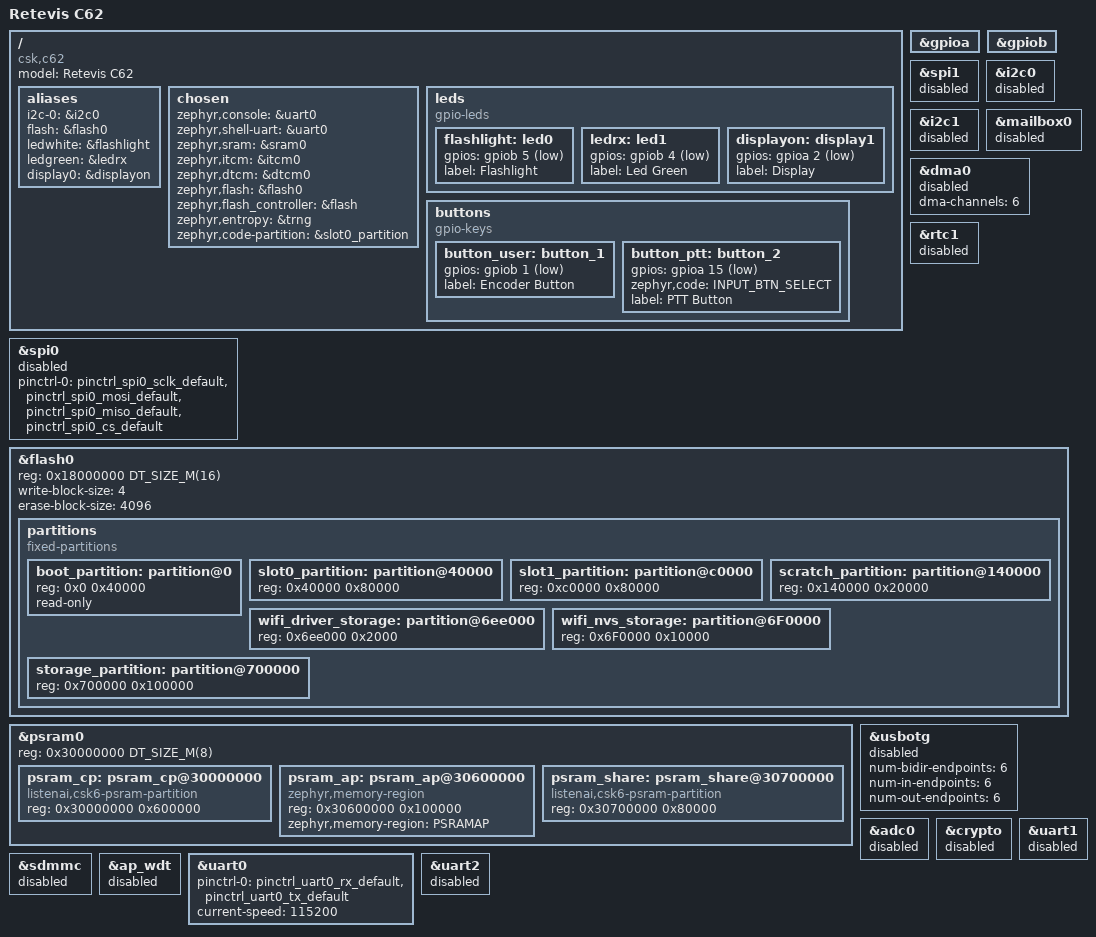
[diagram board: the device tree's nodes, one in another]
/* SPDX-License-Identifier: Apache-2.0 */

/dts-v1/;
#include <csk/csk6011b.dtsi>
#include <zephyr/dt-bindings/pwm/pwm.h>
#include <zephyr/dt-bindings/gpio/gpio.h>
#include <zephyr/dt-bindings/input/input-event-codes.h>
#include "c62_pinctrl.dtsi"

/ {
        model = "Retevis C62";
        compatible = "csk,c62";
        aliases {
                i2c-0 = &i2c0;
                flash = &flash0;

                ledwhite = &flashlight;
                ledgreen = &ledrx;


                display0 = &displayon;
        };

        chosen {
                zephyr,console = &uart0;
                zephyr,shell-uart = &uart0;
                zephyr,sram = &sram0;
                zephyr,itcm = &itcm0;
                zephyr,dtcm = &dtcm0;
                zephyr,flash = &flash0;
                zephyr,flash_controller = &flash;
                zephyr,entropy = &trng;
                zephyr,code-partition = &slot0_partition;
                /* other chosen settings  for your hardware */
        };

        leds {
                compatible = "gpio-leds";
                flashlight: led0 {
                        gpios = <&gpiob 5 GPIO_ACTIVE_LOW>;
                        label = "Flashlight";
                };
                ledrx: led1 {
                        gpios = <&gpiob 4 GPIO_ACTIVE_LOW>;
                        label = "Led Green";
                };
                displayon: display1 {
                        gpios = <&gpioa 2 GPIO_ACTIVE_LOW>;
                        label = "Display";
                };
        };

        buttons: buttons  {
                compatible = "gpio-keys";
                
                button_user: button_1 {
                        gpios = <&gpiob 1 (GPIO_PULL_UP | GPIO_ACTIVE_LOW)>;
                        label = "Encoder Button";
                };
                
                button_ptt: button_2 {
                        gpios = <&gpioa 15 (GPIO_PULL_UP | GPIO_ACTIVE_LOW)>;
                        zephyr,code = <INPUT_BTN_SELECT>;
                        label = "PTT Button";
                };
        };


        /*
         * Your board-specific hardware: buttons, LEDs, sensors, etc.
         */
};


&gpioa {
        status = "okay";
};

&gpiob {
        status = "okay";
};

&spi0 {
        pinctrl-0 = <&pinctrl_spi0_sclk_default &pinctrl_spi0_mosi_default &pinctrl_spi0_miso_default &pinctrl_spi0_cs_default>;
        pinctrl-names = "default";
        status = "disabled";
};

&spi1 {
        status = "disabled";
};

&i2c0 {
        status = "disabled";
};

&i2c1 {
        status = "disabled";
};

&mailbox0 {
        status = "disabled";
};

&dma0 {
        dma-channels = <6>;
        status = "disabled";
};

&rtc1 {
        status = "disabled";
};

&flash0 {
        /*
         * For more information, see:
         * http: //docs.zephyrproject.org/latest/guides/dts/index.html#flash-partitions
         */
        reg = <0x18000000 DT_SIZE_M(16)>;
        write-block-size = <4>;
        erase-block-size = <4096>;
        partitions {
                compatible = "fixed-partitions";
                #address-cells = <1>;
                #size-cells = <1>;

                /* 256KB for bootloader */
                boot_partition: partition@0 {
                        reg = <0x0 0x40000>;
                        read-only;
                };

                /* application image slot: 512KB */
                slot0_partition: partition@40000 {
                        reg = <0x40000 0x80000>;
                };

                /* backup slot: 512KB */
                slot1_partition: partition@c0000 {
                        reg = <0xc0000 0x80000>;
                };

                /* swap slot: 128KB */
                scratch_partition: partition@140000 {
                        reg = <0x140000 0x20000>;
                };

                /* wifi driver private storage: 8Kb */
                wifi_driver_storage: partition@6ee000 {
                        reg = <0x6ee000 0x2000>;
                };

                /* wifi_nvs_storage: 20Kb */
                wifi_nvs_storage: partition@6F0000 {
                        reg = <0x6F0000 0x10000>;
                };

                /* storage: 6.625MB for storage */
                storage_partition: partition@700000 {
                        reg = <0x700000 0x100000>;
                };


        };
};

&psram0 {
        reg = <0x30000000 DT_SIZE_M(8)>;
        #address-cells = <1>;
        #size-cells = <1>;

        /*psram for cp core slot: 6MB */
        psram_cp: psram_cp@30000000 {
                compatible = "listenai,csk6-psram-partition";
                reg = <0x30000000 0x600000>;
                status = "okay";
        };

        /*psram for ap core slot: 1MB */
        psram_ap: psram_ap@30600000 {
                compatible = "zephyr,memory-region",
                             "listenai,csk6-psram-partition";
                reg = <0x30600000 0x100000>;
                status = "okay";
                zephyr,memory-region = "PSRAMAP";
        };

        /*psram for ap share with cp slot: 512KB */
        psram_share: psram_share@30700000 {
                compatible = "listenai,csk6-psram-partition";
                reg = <0x30700000 0x80000>;
                status = "okay";
        };
};

zephyr_udc0: &usbotg {
        status = "disabled";
        num-bidir-endpoints = <6>;
        num-in-endpoints = <6>;
        num-out-endpoints = <6>;
};


&adc0 {
        status = "disabled";
};

&crypto {
        status = "disabled";
};

&sdmmc {
        status = "disabled";
};

&ap_wdt {
        status = "disabled";
};

&uart0 {
        pinctrl-0 = <&pinctrl_uart0_rx_default &pinctrl_uart0_tx_default>;
        pinctrl-names = "default";
        current-speed = <115200>;
        status = "okay";
};



&uart1 {
    status = "disabled";
};


&uart2 {
    status = "disabled";
};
